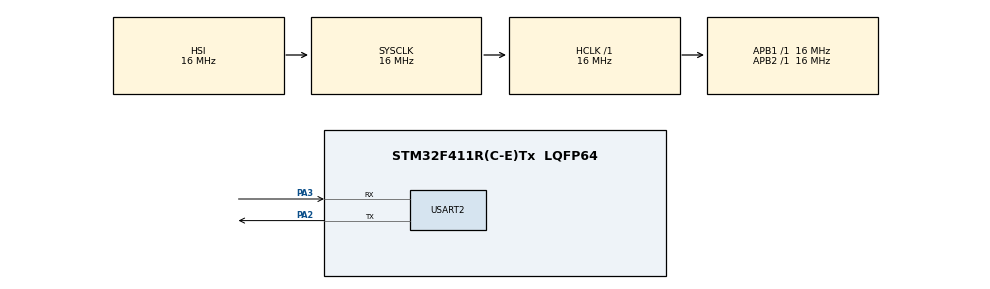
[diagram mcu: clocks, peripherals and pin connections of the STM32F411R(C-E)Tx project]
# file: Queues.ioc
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FREERTOS.Queues01=Queue1,8,uint8_t,0,Dynamic,NULL,NULL
FREERTOS.Tasks01=Sender1,24,256,StartSender1,Default,NULL,Dynamic,NULL,NULL;Receiver,16,256,StartReceiver,Default,NULL,Dynamic,NULL,NULL
FREERTOS.configUSE_NEWLIB_REENTRANT=1
Mcu.Family=STM32F4
Mcu.Name=STM32F411R(C-E)Tx
Mcu.Package=LQFP64
NVIC.PriorityGroup=NVIC_PRIORITYGROUP_4
NVIC.TIM1_UP_TIM10_IRQn=true\:15\:0\:false\:false\:true\:false\:false\:true\:true
NVIC.TimeBase=TIM1_UP_TIM10_IRQn
NVIC.TimeBaseIP=TIM10
PA13.Mode=Serial_Wire
PA13.Signal=SYS_JTMS-SWDIO
PA14.Mode=Serial_Wire
PA14.Signal=SYS_JTCK-SWCLK
PA2.Mode=Asynchronous
PA2.Signal=USART2_TX
PA3.Mode=Asynchronous
PA3.Signal=USART2_RX
ProjectManager.HeapSize=0x200
ProjectManager.StackSize=0x400
ProjectManager.TargetToolchain=STM32CubeIDE
RCC.AHBFreq_Value=16000000
RCC.APB1Freq_Value=16000000
RCC.APB2Freq_Value=16000000
RCC.CortexFreq_Value=16000000
RCC.HSE_VALUE=25000000
RCC.HSI_VALUE=16000000
RCC.LSE_VALUE=32768
RCC.SYSCLKFreq_VALUE=16000000
RCC.VCOOutputFreq_Value=192000000
USART2.VirtualMode=VM_ASYNC
VP_FREERTOS_VS_CMSIS_V2.Mode=CMSIS_V2
VP_SYS_VS_tim10.Mode=TIM10
board=custom

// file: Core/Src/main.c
/* USER CODE BEGIN Header */
/**
  ******************************************************************************
  * @file           : main.c
  * @brief          : Main program body
  ******************************************************************************
  * @attention
  *
  * Copyright (c) 2025 STMicroelectronics.
  * All rights reserved.
  *
  * This software is licensed under terms that can be found in the LICENSE file
  * in the root directory of this software component.
  * If no LICENSE file comes with this software, it is provided AS-IS.
  *
  ******************************************************************************
  */
/* USER CODE END Header */
#include "main.h"
#include "cmsis_os.h"

/* USER CODE BEGIN Includes */
#include "stdio.h"
/* USER CODE END Includes */

UART_HandleTypeDef huart2;

/* Definitions for Sender1 */
osThreadId_t Sender1Handle;
const osThreadAttr_t Sender1_attributes = {
  .name = "Sender1",
  .stack_size = 256 * 4,
  .priority = (osPriority_t) osPriorityNormal,
};
/* Definitions for Receiver */
osThreadId_t ReceiverHandle;
const osThreadAttr_t Receiver_attributes = {
  .name = "Receiver",
  .stack_size = 256 * 4,
  .priority = (osPriority_t) osPriorityBelowNormal,
};
/* Definitions for Queue1 */
osMessageQueueId_t Queue1Handle;
const osMessageQueueAttr_t Queue1_attributes = {
  .name = "Queue1"
};
/* USER CODE BEGIN PV */
osStatus_t error_state;
/* USER CODE END PV */

void SystemClock_Config(void);
static void MX_GPIO_Init(void);
static void MX_USART2_UART_Init(void);
void StartSender1(void *argument);
void StartReceiver(void *argument);

/* USER CODE BEGIN PFP */
int _write(int file, char *ptr, int len)
{
	int DataIdx;
	for(DataIdx = 0; DataIdx < len; DataIdx++)
	{
		HAL_UART_Transmit(&huart2, (uint8_t *)ptr++, 1, 100);
	}
	return len;
}
/* USER CODE END PFP */

int main(void)
{

  /* MCU Configuration--------------------------------------------------------*/

  /* Reset of all peripherals, Initializes the Flash interface and the Systick. */
  HAL_Init();

  /* Configure the system clock */
  SystemClock_Config();

  /* Initialize all configured peripherals */
  MX_GPIO_Init();
  MX_USART2_UART_Init();

  /* Init scheduler */
  osKernelInitialize();

  /* Create the queue(s) */
  /* creation of Queue1 */
  Queue1Handle = osMessageQueueNew (8, sizeof(uint8_t), &Queue1_attributes);

  /* Create the thread(s) */
  /* creation of Sender1 */
  Sender1Handle = osThreadNew(StartSender1, NULL, &Sender1_attributes);

  /* creation of Receiver */
  ReceiverHandle = osThreadNew(StartReceiver, NULL, &Receiver_attributes);

  /* Start scheduler */
  osKernelStart();

  /* We should never get here as control is now taken by the scheduler */
  /* Infinite loop */
  while (1)
  {

  }
}

void SystemClock_Config(void)
{
  RCC_OscInitTypeDef RCC_OscInitStruct = {0};
  RCC_ClkInitTypeDef RCC_ClkInitStruct = {0};

  /** Configure the main internal regulator output voltage
  */
  __HAL_RCC_PWR_CLK_ENABLE();
  __HAL_PWR_VOLTAGESCALING_CONFIG(PWR_REGULATOR_VOLTAGE_SCALE1);

  /** Initializes the RCC Oscillators according to the specified parameters
  * in the RCC_OscInitTypeDef structure.
  */
  RCC_OscInitStruct.OscillatorType = RCC_OSCILLATORTYPE_HSI;
  RCC_OscInitStruct.HSIState = RCC_HSI_ON;
  RCC_OscInitStruct.HSICalibrationValue = RCC_HSICALIBRATION_DEFAULT;
  RCC_OscInitStruct.PLL.PLLState = RCC_PLL_NONE;
  if (HAL_RCC_OscConfig(&RCC_OscInitStruct) != HAL_OK)
  {
    Error_Handler();
  }

  /** Initializes the CPU, AHB and APB buses clocks
  */
  RCC_ClkInitStruct.ClockType = RCC_CLOCKTYPE_HCLK|RCC_CLOCKTYPE_SYSCLK
                              |RCC_CLOCKTYPE_PCLK1|RCC_CLOCKTYPE_PCLK2;
  RCC_ClkInitStruct.SYSCLKSource = RCC_SYSCLKSOURCE_HSI;
  RCC_ClkInitStruct.AHBCLKDivider = RCC_SYSCLK_DIV1;
  RCC_ClkInitStruct.APB1CLKDivider = RCC_HCLK_DIV1;
  RCC_ClkInitStruct.APB2CLKDivider = RCC_HCLK_DIV1;

  if (HAL_RCC_ClockConfig(&RCC_ClkInitStruct, FLASH_LATENCY_0) != HAL_OK)
  {
    Error_Handler();
  }
}

static void MX_USART2_UART_Init(void)
{

  huart2.Instance = USART2;
  huart2.Init.BaudRate = 115200;
  huart2.Init.WordLength = UART_WORDLENGTH_8B;
  huart2.Init.StopBits = UART_STOPBITS_1;
  huart2.Init.Parity = UART_PARITY_NONE;
  huart2.Init.Mode = UART_MODE_TX_RX;
  huart2.Init.HwFlowCtl = UART_HWCONTROL_NONE;
  huart2.Init.OverSampling = UART_OVERSAMPLING_16;
  if (HAL_UART_Init(&huart2) != HAL_OK)
  {
    Error_Handler();
  }

}

static void MX_GPIO_Init(void)
{

  /* GPIO Ports Clock Enable */
  __HAL_RCC_GPIOA_CLK_ENABLE();

}

void StartSender1(void *argument)
{
  /* USER CODE BEGIN 5 */
	uint8_t x = 0;
  /* Infinite loop */
  for(;;)
  {
	  printf("S\r\n");
	  osMessageQueuePut(Queue1Handle, &x, 0, 200);
	  if(++x > 9)
		  x=0;
	  osDelay(1000);
  }
  /* USER CODE END 5 */
}

void StartReceiver(void *argument)
{
  /* USER CODE BEGIN StartReceiver */
	uint8_t res=0;
  /* Infinite loop */
  for(;;)
  {
	  printf("R\r\n");
	  error_state = osMessageQueueGet(Queue1Handle, &res, NULL, osWaitForever);
	  printf("%d\r\n",res);
  }
  /* USER CODE END StartReceiver */
}

void HAL_TIM_PeriodElapsedCallback(TIM_HandleTypeDef *htim)
{
  if (htim->Instance == TIM10) {
    HAL_IncTick();
  }
}

void Error_Handler(void)
{
  __disable_irq();
  while (1)
  {
  }
}
